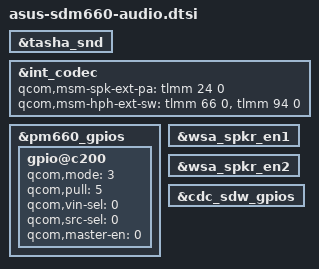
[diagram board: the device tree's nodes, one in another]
// SPDX-License-Identifier: GPL-2.0
// Copyright (C) 2021 Atom-X-Devs < https://www.github.com/Atom-X-Devs >

// asus msm-audo.dtsi specific changes
#include "asus-sdm636-audio.dtsi"

&tasha_snd {
	status = "ok";
};

&int_codec {
	qcom,msm-spk-ext-pa = <&tlmm 24 0>;
	qcom,msm-hph-ext-sw = <&tlmm 66 0>, <&tlmm 94 0>;
};

&pm660_gpios {
	gpio@c200 {
		qcom,mode = <3>; /* Analog Pass Through */
		qcom,pull = <5>; /* Input No pull */
		qcom,vin-sel = <0>; /* VIN0 */
		qcom,src-sel = <0>; /* Constant */
		qcom,master-en = <0>; /* Eanble GPIO */

		/delete-property/ qcom,out-strength;
	};
};

&wsa_spkr_en1 {
	/delete-property/ status;
};

&wsa_spkr_en2 {
	/delete-property/ status;
};

// asus sdm660-internal-codec.dtsi specific diff
&cdc_sdw_gpios {
	/delete-property/ status;
};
